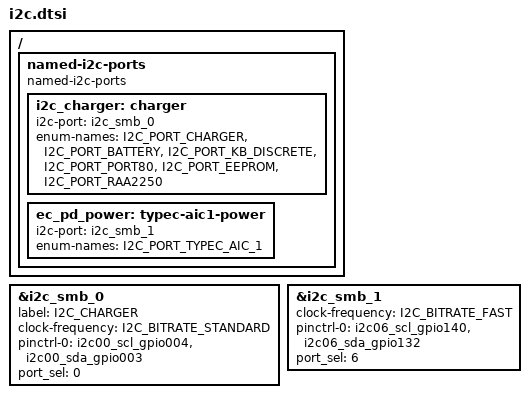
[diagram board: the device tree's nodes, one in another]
/* Copyright 2024 The ChromiumOS Authors
 * Use of this source code is governed by a BSD-style license that can be
 * found in the LICENSE file.
 */

/ {
	named-i2c-ports {
		compatible = "named-i2c-ports";

		i2c_charger: charger {
			i2c-port = <&i2c_smb_0>;
			enum-names = "I2C_PORT_CHARGER",
				"I2C_PORT_BATTERY",
				"I2C_PORT_KB_DISCRETE",
				"I2C_PORT_PORT80",
				"I2C_PORT_EEPROM",
				"I2C_PORT_RAA2250";
		};
		ec_pd_power: typec-aic1-power {
			i2c-port = <&i2c_smb_1>;
			enum-names = "I2C_PORT_TYPEC_AIC_1";
		};
	};
};

/* charger */
&i2c_smb_0 {
	label = "I2C_CHARGER";
	clock-frequency = <I2C_BITRATE_STANDARD>;
	pinctrl-0 = <&i2c00_scl_gpio004 &i2c00_sda_gpio003>;
	pinctrl-names = "default";
	port_sel = <0>;
	status = "okay";
};

/* typec-aic1-power */
&i2c_smb_1 {
	clock-frequency = <I2C_BITRATE_FAST>;
	pinctrl-0 = <&i2c06_scl_gpio140 &i2c06_sda_gpio132>;
	pinctrl-names = "default";
	port_sel = <6>;
	status = "okay";
};
